# M55M1 register map
File version: 1.0
Registers are 32-bit, read-write, reset 0x0 unless marked. A register's access mark holds for its fields unless they carry their own. Offsets are from the block's base; [hi:lo] are bit positions; {n}, {i} and the like mark numbered series; 'fields as' and 'values as' point back to an identical list.

## PLM — SCU Register Map
Base 0x40402700
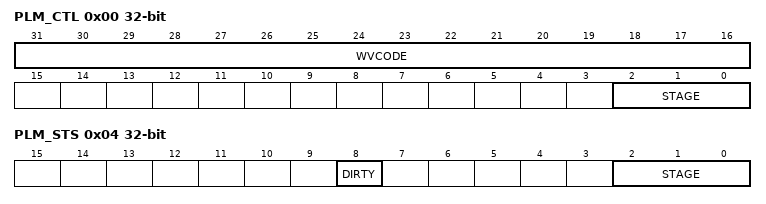
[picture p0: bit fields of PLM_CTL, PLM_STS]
0x00 PLM_CTL (reset mask 0xFFFFFFF0) — Product Life-cycle Control Register
  [31:16] WVCODE — Write Verify Code. The code is 0x475A for a valid write to this register.
  [2:0] STAGE — Life-cycle Stage Update Bits. Bits to update PLM stage. All bits can be set to one but cannot be cleared to 0. Other value will be ignored.
    1=progress to OEM stage; 3=progress to Deployed stage; 7=progress to RMA stage
0x04 PLM_STS ro (reset mask 0xFFFFFFF0) — Product Life-cycle Status Register
  [8] DIRTY — DIRTY Bit (Read Only). Indicate the life-cycle stage has been progressed after last cold-reset. Value of STAGE bits is not Current stage of PLM. It needs a cold reset to make it work.
  [2:0] STAGE — Life-cycle Stage (Read Only). Indicates the current stage of PLM.
    0=Vendor Stage; 1=OEM Stage; 3=Deployed Stage; 7=RMA Stage

## TRNG — TRNG Register Map
Base 0x40296000
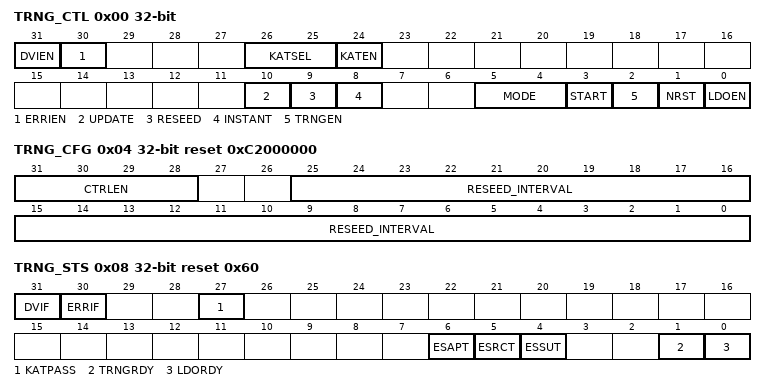
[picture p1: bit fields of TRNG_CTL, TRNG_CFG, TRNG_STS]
0x00 TRNG_CTL — TRNG Control Register
  [31] DVIEN — Data Valid Interrupt Enable Bit
    0=Interrupt Disabled; 1=Interrupt Enabled
  [30] ERRIEN — TRNG Error Interrupt Enable Bit
    0=Error interrupt Disabled; 1=Error interrupt Enabled
  [26:25] KATSEL — CTR_DRBG Known Answer Test Selection
    0=Instantiation testing; 1=Reseed testing; 2=Generation testing
  [24] KATEN — CTR_DRBG Known Answer Test Enable Bit. Note: Do not enable START and KATEN at the same time.
    0=Disabled; 1=Enabled
  [10] UPDATE — CTR_DRBG User Manual Update Function
    0=No effect; 1=Enable CTR_DRBG update function
  [9] RESEED — CTR_DRBG User Manual Reseed Function
    0=No effect; 1=Enable CTR_DRBG reseed function
  [8] INSTANT — CTR_DRBG User Manual Instant Function
    0=No effect; 1=Enable CTR_DRBG instant function
  [5:4] MODE — Random Bit Generator Output Selection
    0=Output data is from entropy (32-bits); 1=Output data is from NRBG (128-bits); 2=Output data is from DRBG (128-bits)
  [3] START — True Random Number Generator Start. Note: Do not enable START and KATEN at the same time. This bit is always 0 when it is read back.
    0=No effect; 1=Start TRNG
  [2] TRNGEN — True Random Number Generator Macro Enable Bit
    0=TRNG macro Disabled; 1=TRNG macro Enabled
  [1] NRST — Negative-edge Trigger Reset
    0=Keep reset; 1=No reset
  [0] LDOEN — LDO Enable Bit
    0=LDO Disabled; 1=LDO Enabled
0x04 TRNG_CFG reset 0xC2000000 — TRNG Configure Register
  [31:28] CTRLEN — CTR_DRBG Bits Length Per Request
  [25:0] RESEED_INTERVAL — Reseed Interval. Maximum number of requests between reseeds. The value is 1 ~ 225 .
0x08 TRNG_STS ro reset 0x60 — TRNG Status Register
  [31] DVIF — Data Valid Interrupt Flag
    0=Data is invalid; 1=Data is valid. A valid random number can be read form TRNG_DATAx
  [30] ERRIF — TRNG Error Interrupt Flag
    0=No TRNG error; 1=TRNGRDY became '0' for a while, TRNG error interrupt
  [27] KATPASS — CTR_DRBG Known Answer Test Pass. Note: When users enable KATEN, they can check this bit after DVIF become '1'.
    0=Test fail; 1=Test pass
  [6] ESAPT — Entropy Source Adaptive Proportion Test
    0=Entropy source is still under testing or test fail; 1=Test pass
  [5] ESRCT — Entropy Source Repetition Count Test
    values as ESAPT
  [4] ESSUT — Entropy Source Start-Up Test
    values as ESAPT
  [1] TRNGRDY — TRNG Ready Signal
    0=True random number generator is not ready; 1=True random number generator is ready
  [0] LDORDY — LDO Ready Signal
    0=LDO is not ready; 1=LDO is ready
{0xC+4i} TRNG_DATA{i} ro (i=0..3) — TRNG Data Output Word {i} Register
  [31:0] DATA — True Random Number Generator Data (Read Only). The DATA stores the output data generated by TRNG, it can be read when DVIF become 1 and can be read only once. TRNG_DATA0 stores Entropy / NRBG word 0 / DRBG word 0. TRNG_DATA1 stores NRBG word 1 / DRBG word 1. TRNG_DATA2 stores NRBG word 2 / DRBG word 2. TRNG_DATA3 stores NRBG word 3 / DRBG word 3.
